# ESP32-S2 register map
Vendor: ESPRESSIF SYSTEMS (SHANGHAI) CO., LTD.; Series: ESP32 S-Series; File version: 20
CPU: Xtensa LX7 r0p0, little endian, no MPU, no FPU, 0 interrupt priority bits
Address unit: 32 bits
Registers are 32-bit, read-write, reset 0x0 unless marked. A register's access mark holds for its fields unless they carry their own. Offsets are from the block's base; [hi:lo] are bit positions; {n}, {i} and the like mark numbered series.

## INTERRUPT_CORE0 — Interrupt Controller (Core 0)
Base 0x3F4C2000
0x00 INTERRUPT_PRO_MAC_INTR_MAP reset 0x10 — MAC_INTR interrupt configuration register
  [4:0] INTERRUPT_PRO_MAC_INTR_MAP — This register is used to map MAC_INTR interrupt signal to one of the CPU interrupts.
0x04 INTERRUPT_PRO_MAC_NMI_MAP reset 0x10 — MAC_NMI interrupt configuration register
  [4:0] INTERRUPT_PRO_MAC_NMI_MAP — This register is used to map MAC_NMI interrupt signal to one of the CPU interrupts.
0x08 INTERRUPT_PRO_PWR_INTR_MAP reset 0x10 — PWR_INTR interrupt configuration register
  [4:0] INTERRUPT_PRO_PWR_INTR_MAP — This register is used to map PWR_INTR interrupt signal to one of the CPU interrupts.
0x0C INTERRUPT_PRO_BB_INT_MAP reset 0x10 — BB_INT interrupt configuration register
  [4:0] INTERRUPT_PRO_BB_INT_MAP — This register is used to map BB_INT interrupt signal to one of the CPU interrupts.
0x10 INTERRUPT_PRO_BT_MAC_INT_MAP reset 0x10 — BT_MAC_INT interrupt configuration register
  [4:0] INTERRUPT_PRO_BT_MAC_INT_MAP — This register is used to map BT_MAC_INT interrupt signal to one of the CPU interrupts.
0x14 INTERRUPT_PRO_BT_BB_INT_MAP reset 0x10 — BT_BB_INT interrupt configuration register
  [4:0] INTERRUPT_PRO_BT_BB_INT_MAP — This register is used to map BT_BB_INT interrupt signal to one of the CPU interrupts.
0x18 INTERRUPT_PRO_BT_BB_NMI_MAP reset 0x10 — BT_BB_NMI interrupt configuration register
  [4:0] INTERRUPT_PRO_BT_BB_NMI_MAP — This register is used to map BT_BB_NMI interrupt signal to one of the CPU interrupts.
0x1C INTERRUPT_PRO_RWBT_IRQ_MAP reset 0x10 — RWBT_IRQ interrupt configuration register
  [4:0] INTERRUPT_PRO_RWBT_IRQ_MAP — This register is used to map RWBT_IRQ interrupt signal to one of the CPU interrupts.
0x20 INTERRUPT_PRO_RWBLE_IRQ_MAP reset 0x10 — RWBLE_IRQ interrupt configuration register
  [4:0] INTERRUPT_PRO_RWBLE_IRQ_MAP — This register is used to map RWBLE_IRQ interrupt signal to one of the CPU interrupts.
0x24 INTERRUPT_PRO_RWBT_NMI_MAP reset 0x10 — RWBT_NMI interrupt configuration register
  [4:0] INTERRUPT_PRO_RWBT_NMI_MAP — This register is used to map RWBT_NMI interrupt signal to one of the CPU interrupts.
0x28 INTERRUPT_PRO_RWBLE_NMI_MAP reset 0x10 — RWBLE_NMI interrupt configuration register
  [4:0] INTERRUPT_PRO_RWBLE_NMI_MAP — This register is used to map RWBLE_NMI interrupt signal to one of the CPU interrupts.
0x2C INTERRUPT_PRO_SLC0_INTR_MAP reset 0x10 — SLC0_INTR interrupt configuration register
  [4:0] INTERRUPT_PRO_SLC0_INTR_MAP — This register is used to map SLC0_INTR interrupt signal to one of the CPU interrupts.
0x30 INTERRUPT_PRO_SLC1_INTR_MAP reset 0x10 — SLC1_INTR interrupt configuration register
  [4:0] INTERRUPT_PRO_SLC1_INTR_MAP — This register is used to map SLC1_INTR interrupt signal to one of the CPU interrupts.
0x34 INTERRUPT_PRO_UHCI0_INTR_MAP reset 0x10 — UHCI0_INTR interrupt configuration register
  [4:0] INTERRUPT_PRO_UHCI0_INTR_MAP — This register is used to map UHCI0_INTR interrupt signal to one of the CPU interrupts.
0x38 INTERRUPT_PRO_UHCI1_INTR_MAP reset 0x10 — UHCI1_INTR interrupt configuration register
  [4:0] INTERRUPT_PRO_UHCI1_INTR_MAP — This register is used to map UHCI1_INTR interrupt signal to one of the CPU interrupts.
0x3C INTERRUPT_PRO_TG_T0_LEVEL_INT_MAP reset 0x10 — TG_T0_LEVEL_INT interrupt configuration register
  [4:0] INTERRUPT_PRO_TG_T0_LEVEL_INT_MAP — This register is used to map TG_T0_LEVEL_INT interrupt signal to one of the CPU interrupts.
0x40 INTERRUPT_PRO_TG_T1_LEVEL_INT_MAP reset 0x10 — TG_T1_LEVEL_INT interrupt configuration register
  [4:0] INTERRUPT_PRO_TG_T1_LEVEL_INT_MAP — This register is used to map TG_T1_LEVEL_INT interrupt signal to one of the CPU interrupts.
0x44 INTERRUPT_PRO_TG_WDT_LEVEL_INT_MAP reset 0x10 — TG_WDT_LEVEL_INT interrupt configuration register
  [4:0] INTERRUPT_PRO_TG_WDT_LEVEL_INT_MAP — This register is used to map TG_WDT_LEVEL_INT interrupt signal to one of the CPU interrupts.
0x48 INTERRUPT_PRO_TG_LACT_LEVEL_INT_MAP reset 0x10 — TG_LACT_LEVEL_INT interrupt configuration register
  [4:0] INTERRUPT_PRO_TG_LACT_LEVEL_INT_MAP — This register is used to map TG_LACT_LEVEL_INT interrupt signal to one of the CPU interrupts.
0x4C INTERRUPT_PRO_TG1_T0_LEVEL_INT_MAP reset 0x10 — TG1_T0_LEVEL_INT interrupt configuration register
  [4:0] INTERRUPT_PRO_TG1_T0_LEVEL_INT_MAP — This register is used to map TG1_T0_LEVEL_INT interrupt signal to one of the CPU interrupts.
0x50 INTERRUPT_PRO_TG1_T1_LEVEL_INT_MAP reset 0x10 — TG1_T1_LEVEL_INT interrupt configuration register
  [4:0] INTERRUPT_PRO_TG1_T1_LEVEL_INT_MAP — This register is used to map TG1_T1_LEVEL_INT interrupt signal to one of the CPU interrupts.
0x54 INTERRUPT_PRO_TG1_WDT_LEVEL_INT_MAP reset 0x10 — TG1_WDT_LEVEL_INT interrupt configuration register
  [4:0] INTERRUPT_PRO_TG1_WDT_LEVEL_INT_MAP — This register is used to map TG1_WDT_LEVEL_INT interrupt signal to one of the CPU interrupts.
0x58 INTERRUPT_PRO_TG1_LACT_LEVEL_INT_MAP reset 0x10 — TG1_LACT_LEVEL_INT interrupt configuration register
  [4:0] INTERRUPT_PRO_TG1_LACT_LEVEL_INT_MAP — This register is used to map TG1_LACT_LEVEL_INT interrupt signal to one of the CPU interrupts.
0x5C INTERRUPT_PRO_GPIO_INTERRUPT_PRO_MAP reset 0x10 — GPIO_INTERRUPT_PRO interrupt configuration register
  [4:0] INTERRUPT_PRO_GPIO_INTERRUPT_PRO_MAP — This register is used to map GPIO_INTERRUPT_PRO interrupt signal to one of the CPU interrupts.
0x60 INTERRUPT_PRO_GPIO_INTERRUPT_PRO_NMI_MAP reset 0x10 — GPIO_INTERRUPT_PRO_NMI interrupt configuration register
  [4:0] INTERRUPT_PRO_GPIO_INTERRUPT_PRO_NMI_MAP — This register is used to map GPIO_INTERRUPT_PRO_NMI interrupt signal to one of the CPU interrupts.
0x64 INTERRUPT_PRO_GPIO_INTERRUPT_APP_MAP reset 0x10 — GPIO_INTERRUPT_APP interrupt configuration register
  [4:0] INTERRUPT_PRO_GPIO_INTERRUPT_APP_MAP — This register is used to map GPIO_INTERRUPT_APP interrupt signal to one of the CPU interrupts.
0x68 INTERRUPT_PRO_GPIO_INTERRUPT_APP_NMI_MAP reset 0x10 — GPIO_INTERRUPT_APP_NMI interrupt configuration register
  [4:0] INTERRUPT_PRO_GPIO_INTERRUPT_APP_NMI_MAP — This register is used to map GPIO_INTERRUPT_APP_NMI interrupt signal to one of the CPU interrupts.
0x6C INTERRUPT_PRO_DEDICATED_GPIO_IN_INTR_MAP reset 0x10 — DEDICATED_GPIO_IN_INTR interrupt configuration register
  [4:0] INTERRUPT_PRO_DEDICATED_GPIO_IN_INTR_MAP — This register is used to map DEDICATED_GPIO_IN_INTR interrupt signal to one of the CPU interrupts.
{0x70+4i} INTERRUPT_PRO_CPU_INTR_FROM_CPU_{i}_MAP reset 0x10 (i=0..3) — CPU_INTR_FROM_CPU_{i} interrupt configuration register
  [4:0] INTERRUPT_PRO_CPU_INTR_FROM_CPU_{i}_MAP — This register is used to map CPU_INTR_FROM_CPU_{i} interrupt signal to one of the CPU interrupts.
{0x7C+4i} INTERRUPT_PRO_SPI_INTR_{i}_MAP reset 0x10 (i=1..3) — SPI_INTR_{i} interrupt configuration register
  [4:0] INTERRUPT_PRO_SPI_INTR_{i}_MAP — This register is used to map SPI_INTR_{i} interrupt signal to one of the CPU interrupts.
0x8C INTERRUPT_PRO_I2S0_INT_MAP reset 0x10 — I2S0_INT interrupt configuration register
  [4:0] INTERRUPT_PRO_I2S0_INT_MAP — This register is used to map I2S0_INT interrupt signal to one of the CPU interrupts.
0x90 INTERRUPT_PRO_I2S1_INT_MAP reset 0x10 — I2S1_INT interrupt configuration register
  [4:0] INTERRUPT_PRO_I2S1_INT_MAP — This register is used to map I2S1_INT interrupt signal to one of the CPU interrupts.
0x94 INTERRUPT_PRO_UART_INTR_MAP reset 0x10 — UART_INT interrupt configuration register
  [4:0] INTERRUPT_PRO_UART_INTR_MAP — This register is used to map UART_INT interrupt signal to one of the CPU interrupts.
0x98 INTERRUPT_PRO_UART1_INTR_MAP reset 0x10 — UART1_INT interrupt configuration register
  [4:0] INTERRUPT_PRO_UART1_INTR_MAP — This register is used to map UART1_INT interrupt signal to one of the CPU interrupts.
0x9C INTERRUPT_PRO_UART2_INTR_MAP reset 0x10 — UART2_INT interrupt configuration register
  [4:0] INTERRUPT_PRO_UART2_INTR_MAP — This register is used to map UART2_INT interrupt signal to one of the CPU interrupts.
0xA0 INTERRUPT_PRO_SDIO_HOST_INTERRUPT_MAP reset 0x10 — SDIO_HOST_INTERRUPT configuration register
  [4:0] INTERRUPT_PRO_SDIO_HOST_INTERRUPT_MAP — This register is used to map SDIO_HOST_INTERRUPT signal to one of the CPU interrupts.
{0xA4+4i} INTERRUPT_PRO_PWM{i}_INTR_MAP reset 0x10 (i=0..3) — PWM{i}_INTR interrupt configuration register
  [4:0] INTERRUPT_PRO_PWM{i}_INTR_MAP — This register is used to map PWM{i}_INTR interrupt signal to one of the CPU interrupts.
0xB4 INTERRUPT_PRO_LEDC_INT_MAP reset 0x10 — LEDC_INTR interrupt configuration register
  [4:0] INTERRUPT_PRO_LEDC_INT_MAP — This register is used to map LEDC_INTR interrupt signal to one of the CPU interrupts.
0xB8 INTERRUPT_PRO_EFUSE_INT_MAP reset 0x10 — EFUSE_INT interrupt configuration register
  [4:0] INTERRUPT_PRO_EFUSE_INT_MAP — This register is used to map EFUSE_INT interrupt signal to one of the CPU interrupts.
0xBC INTERRUPT_PRO_CAN_INT_MAP reset 0x10 — CAN_INT interrupt configuration register
  [4:0] INTERRUPT_PRO_CAN_INT_MAP — This register is used to map CAN_INT interrupt signal to one of the CPU interrupts.
0xC0 INTERRUPT_PRO_USB_INTR_MAP reset 0x10 — USB_INT interrupt configuration register
  [4:0] INTERRUPT_PRO_USB_INTR_MAP — This register is used to map USB_INT interrupt signal to one of the CPU interrupts.
0xC4 INTERRUPT_PRO_RTC_CORE_INTR_MAP reset 0x10 — RTC_CORE_INTR interrupt configuration register
  [4:0] INTERRUPT_PRO_RTC_CORE_INTR_MAP — This register is used to map RTC_CORE_INTR interrupt signal to one of the CPU interrupts.
0xC8 INTERRUPT_PRO_RMT_INTR_MAP reset 0x10 — RMT_INTR interrupt configuration register
  [4:0] INTERRUPT_PRO_RMT_INTR_MAP — This register is used to map RMT_INTR interrupt signal to one of the CPU interrupts.
0xCC INTERRUPT_PRO_PCNT_INTR_MAP reset 0x10 — PCNT_INTR interrupt configuration register
  [4:0] INTERRUPT_PRO_PCNT_INTR_MAP — This register is used to map PCNT_INTR interrupt signal to one of the CPU interrupts.
0xD0 INTERRUPT_PRO_I2C_EXT0_INTR_MAP reset 0x10 — I2C_EXT0_INTR interrupt configuration register
  [4:0] INTERRUPT_PRO_I2C_EXT0_INTR_MAP — This register is used to map I2C_EXT0_INTR interrupt signal to one of the CPU interrupts.
0xD4 INTERRUPT_PRO_I2C_EXT1_INTR_MAP reset 0x10 — I2C_EXT1_INTR interrupt configuration register
  [4:0] INTERRUPT_PRO_I2C_EXT1_INTR_MAP — This register is used to map I2C_EXT1_INTR interrupt signal to one of the CPU interrupts.
0xD8 INTERRUPT_PRO_RSA_INTR_MAP reset 0x10 — RSA_INTR interrupt configuration register
  [4:0] INTERRUPT_PRO_RSA_INTR_MAP — This register is used to map RSA_INTR interrupt signal to one of the CPU interrupts.
0xDC INTERRUPT_PRO_SHA_INTR_MAP reset 0x10 — SHA_INTR interrupt configuration register
  [4:0] INTERRUPT_PRO_SHA_INTR_MAP — This register is used to map SHA_INTR interrupt signal to one of the CPU interrupts.
0xE0 INTERRUPT_PRO_AES_INTR_MAP reset 0x10 — AES_INTR interrupt configuration register
  [4:0] INTERRUPT_PRO_AES_INTR_MAP — This register is used to map AES_INTR interrupt signal to one of the CPU interrupts.
0xE4 INTERRUPT_PRO_SPI2_DMA_INT_MAP reset 0x10 — SPI2_DMA_INT interrupt configuration register
  [4:0] INTERRUPT_PRO_SPI2_DMA_INT_MAP — This register is used to map AES_INTR interrupt signal to one of the CPU interrupts.
0xE8 INTERRUPT_PRO_SPI3_DMA_INT_MAP reset 0x10 — SPI3_DMA_INT interrupt configuration register
  [4:0] INTERRUPT_PRO_SPI3_DMA_INT_MAP — This register is used to map SPI3_DMA_INT dma interrupt signal to one of the CPU interrupts.
0xEC INTERRUPT_PRO_WDG_INT_MAP reset 0x10 — WDG_INT interrupt configuration register
  [4:0] INTERRUPT_PRO_WDG_INT_MAP — This register is used to map WDG_INT interrupt signal to one of the CPU interrupts.
0xF0 INTERRUPT_PRO_TIMER_INT1_MAP reset 0x10 — TIMER_INT1 interrupt configuration register
  [4:0] INTERRUPT_PRO_TIMER_INT1_MAP — This register is used to map TIMER_INT1 interrupt signal to one of the CPU interrupts.
0xF4 INTERRUPT_PRO_TIMER_INT2_MAP reset 0x10 — TIMER_INT2 interrupt configuration register
  [4:0] INTERRUPT_PRO_TIMER_INT2_MAP — This register is used to map TIMER_INT2 interrupt signal to one of the CPU interrupts.
0xF8 INTERRUPT_PRO_TG_T0_EDGE_INT_MAP reset 0x10 — TG_T0_EDGE_INT interrupt configuration register
  [4:0] INTERRUPT_PRO_TG_T0_EDGE_INT_MAP — This register is used to map TG_T0_EDGE_INT interrupt signal to one of the CPU interrupts.
0xFC INTERRUPT_PRO_TG_T1_EDGE_INT_MAP reset 0x10 — TG_T1_EDGE_INT interrupt configuration register
  [4:0] INTERRUPT_PRO_TG_T1_EDGE_INT_MAP — This register is used to map TG_T1_EDGE_INT interrupt signal to one of the CPU interrupts.
0x100 INTERRUPT_PRO_TG_WDT_EDGE_INT_MAP reset 0x10 — TG_WDT_EDGE_INT interrupt configuration register
  [4:0] INTERRUPT_PRO_TG_WDT_EDGE_INT_MAP — This register is used to map TG_WDT_EDGE_INT interrupt signal to one of the CPU interrupts.
0x104 INTERRUPT_PRO_TG_LACT_EDGE_INT_MAP reset 0x10 — TG_LACT_EDGE_INT interrupt configuration register
  [4:0] INTERRUPT_PRO_TG_LACT_EDGE_INT_MAP — This register is used to map TG_LACT_EDGE_INT interrupt signal to one of the CPU interrupts.
0x108 INTERRUPT_PRO_TG1_T0_EDGE_INT_MAP reset 0x10 — TG1_T0_EDGE_INT interrupt configuration register
  [4:0] INTERRUPT_PRO_TG1_T0_EDGE_INT_MAP — This register is used to map TG1_T0_EDGE_INT interrupt signal to one of the CPU interrupts.
0x10C INTERRUPT_PRO_TG1_T1_EDGE_INT_MAP reset 0x10 — TG1_T1_EDGE_INT interrupt configuration register
  [4:0] INTERRUPT_PRO_TG1_T1_EDGE_INT_MAP — This register is used to map TG1_T1_EDGE_INT interrupt signal to one of the CPU interrupts.
0x110 INTERRUPT_PRO_TG1_WDT_EDGE_INT_MAP reset 0x10 — TG1_WDT_EDGE_INT interrupt configuration register
  [4:0] INTERRUPT_PRO_TG1_WDT_EDGE_INT_MAP — This register is used to map TG1_WDT_EDGE_INT interrupt signal to one of the CPU interrupts.
0x114 INTERRUPT_PRO_TG1_LACT_EDGE_INT_MAP reset 0x10 — TG1_LACT_EDGE_INT interrupt configuration register
  [4:0] INTERRUPT_PRO_TG1_LACT_EDGE_INT_MAP — This register is used to map TG1_LACT_EDGE_INT interrupt signal to one of the CPU interrupts.
0x118 INTERRUPT_PRO_CACHE_IA_INT_MAP reset 0x10 — CACHE_IA_INT interrupt configuration register
  [4:0] INTERRUPT_PRO_CACHE_IA_INT_MAP — This register is used to map CACHE_IA_INT interrupt signal to one of the CPU interrupts.
{0x11C+4i} INTERRUPT_PRO_SYSTIMER_TARGET{i}_INT_MAP reset 0x10 (i=0..2) — SYSTIMER_TARGET{i}_INT interrupt configuration register
  [4:0] INTERRUPT_PRO_SYSTIMER_TARGET{i}_INT_MAP — This register is used to map SYSTIMER_TARGET{i}_INT interrupt signal to one of the CPU interrupts.
0x128 INTERRUPT_PRO_ASSIST_DEBUG_INTR_MAP reset 0x10 — ASSIST_DEBUG_INTR interrupt configuration register
  [4:0] INTERRUPT_PRO_ASSIST_DEBUG_INTR_MAP — This register is used to map ASSIST_DEBUG_INTR interrupt signal to one of the CPU interrupts.
0x12C INTERRUPT_PRO_PMS_PRO_IRAM0_ILG_INTR_MAP reset 0x10 — PMS_PRO_IRAM0_ILG interrupt configuration register
  [4:0] INTERRUPT_PRO_PMS_PRO_IRAM0_ILG_INTR_MAP — This register is used to map PMS_PRO_IRAM0_ILG interrupt signal to one of the CPU interrupts.
0x130 INTERRUPT_PRO_PMS_PRO_DRAM0_ILG_INTR_MAP reset 0x10 — PMS_PRO_DRAM0_ILG interrupt configuration register
  [4:0] INTERRUPT_PRO_PMS_PRO_DRAM0_ILG_INTR_MAP — This register is used to map PMS_PRO_DRAM0_ILG interrupt signal to one of the CPU interrupts.
0x134 INTERRUPT_PRO_PMS_PRO_DPORT_ILG_INTR_MAP reset 0x10 — PMS_PRO_DPORT_ILG interrupt configuration register
  [4:0] INTERRUPT_PRO_PMS_PRO_DPORT_ILG_INTR_MAP — This register is used to map PMS_PRO_DPORT_ILG interrupt signal to one of the CPU interrupts.
0x138 INTERRUPT_PRO_PMS_PRO_AHB_ILG_INTR_MAP reset 0x10 — PMS_PRO_AHB_ILG interrupt configuration register
  [4:0] INTERRUPT_PRO_PMS_PRO_AHB_ILG_INTR_MAP — This register is used to map PMS_PRO_AHB_ILG interrupt signal to one of the CPU interrupts.
0x13C INTERRUPT_PRO_PMS_PRO_CACHE_ILG_INTR_MAP reset 0x10 — PMS_PRO_CACHE_ILG interrupt configuration register
  [4:0] INTERRUPT_PRO_PMS_PRO_CACHE_ILG_INTR_MAP — This register is used to map PMS_PRO_CACHE_ILG interrupt signal to one of the CPU interrupts.
0x140 INTERRUPT_PRO_PMS_DMA_APB_I_ILG_INTR_MAP reset 0x10 — PMS_DMA_APB_I_ILG interrupt configuration register
  [4:0] INTERRUPT_PRO_PMS_DMA_APB_I_ILG_INTR_MAP — This register is used to map PMS_DMA_APB_I_ILG interrupt signal to one of the CPU interrupts.
0x144 INTERRUPT_PRO_PMS_DMA_RX_I_ILG_INTR_MAP reset 0x10 — PMS_DMA_RX_I_ILG interrupt configuration register
  [4:0] INTERRUPT_PRO_PMS_DMA_RX_I_ILG_INTR_MAP — This register is used to map PMS_DMA_RX_I_ILG interrupt signal to one of the CPU interrupts.
0x148 INTERRUPT_PRO_PMS_DMA_TX_I_ILG_INTR_MAP reset 0x10 — PMS_DMA_TX_I_ILG interrupt configuration register
  [4:0] INTERRUPT_PRO_PMS_DMA_TX_I_ILG_INTR_MAP — This register is used to map PMS_DMA_TX_I_ILG interrupt signal to one of the CPU interrupts.
0x14C INTERRUPT_PRO_SPI_MEM_REJECT_INTR_MAP reset 0x10 — SPI_MEM_REJECT_INTR interrupt configuration register
  [4:0] INTERRUPT_PRO_SPI_MEM_REJECT_INTR_MAP — This register is used to map SPI_MEM_REJECT_INTR interrupt signal to one of the CPU interrupts.
0x150 INTERRUPT_PRO_DMA_COPY_INTR_MAP reset 0x10 — DMA_COPY_INTR interrupt configuration register
  [4:0] INTERRUPT_PRO_DMA_COPY_INTR_MAP — This register is used to map DMA_COPY_INTR interrupt signal to one of the CPU interrupts.
0x154 INTERRUPT_PRO_SPI4_DMA_INT_MAP reset 0x10 — SPI4_DMA_INT interrupt configuration register
  [4:0] INTERRUPT_PRO_SPI4_DMA_INT_MAP — This register is used to map SPI4_DMA_INT interrupt signal to one of the CPU interrupts.
0x158 INTERRUPT_PRO_SPI_INTR_4_MAP reset 0x10 — SPI_INTR_4 interrupt configuration register
  [4:0] INTERRUPT_PRO_SPI_INTR_4_MAP — This register is used to map SPI_INTR_4 interrupt signal to one of the CPU interrupts.
0x15C INTERRUPT_PRO_DCACHE_PRELOAD_INT_MAP reset 0x10 — DCACHE_PRELOAD_INT interrupt configuration register
  [4:0] INTERRUPT_PRO_DCACHE_PRELOAD_INT_MAP — This register is used to map DCACHE_PRELOAD_INT interrupt signal to one of the CPU interrupts.
0x160 INTERRUPT_PRO_ICACHE_PRELOAD_INT_MAP reset 0x10 — ICACHE_PRELOAD_INT interrupt configuration register
  [4:0] INTERRUPT_PRO_ICACHE_PRELOAD_INT_MAP — This register is used to map ICACHE_PRELOAD_INT interrupt signal to one of the CPU interrupts.
0x164 INTERRUPT_PRO_APB_ADC_INT_MAP reset 0x10 — APB_ADC_INT interrupt configuration register
  [4:0] INTERRUPT_PRO_APB_ADC_INT_MAP — This register is used to map APB_ADC_INT interrupt signal to one of the CPU interrupts.
0x168 INTERRUPT_PRO_CRYPTO_DMA_INT_MAP reset 0x10 — CRYPTO_DMA_INT interrupt configuration register
  [4:0] INTERRUPT_PRO_CRYPTO_DMA_INT_MAP — This register is used to map CRYPTO_DMA_INT interrupt signal to one of the CPU interrupts.
0x16C INTERRUPT_PRO_CPU_PERI_ERROR_INT_MAP reset 0x10 — CPU_PERI_ERROR_INT interrupt configuration register
  [4:0] INTERRUPT_PRO_CPU_PERI_ERROR_INT_MAP — This register is used to map CPU_PERI_ERROR_INT interrupt signal to one of the CPU interrupts.
0x170 INTERRUPT_PRO_APB_PERI_ERROR_INT_MAP reset 0x10 — APB_PERI_ERROR_INT interrupt configuration register
  [4:0] INTERRUPT_PRO_APB_PERI_ERROR_INT_MAP — This register is used to map APB_PERI_ERROR_INT interrupt signal to one of the CPU interrupts.
0x174 INTERRUPT_PRO_DCACHE_SYNC_INT_MAP reset 0x10 — DCACHE_SYNC_INT interrupt configuration register
  [4:0] INTERRUPT_PRO_DCACHE_SYNC_INT_MAP — This register is used to map DCACHE_SYNC_INT interrupt signal to one of the CPU interrupts.
0x178 INTERRUPT_PRO_ICACHE_SYNC_INT_MAP reset 0x10 — ICACHE_SYNC_INT interrupt configuration register
  [4:0] INTERRUPT_PRO_ICACHE_SYNC_INT_MAP — This register is used to map ICACHE_SYNC_INT interrupt signal to one of the CPU interrupts.
0x17C INTERRUPT_PRO_INTR_STATUS_REG_0 ro — Interrupt status register 0
  [31:0] INTERRUPT_PRO_INTR_STATUS_0 — This register stores the status of the first 32 input interrupt sources.
0x180 INTERRUPT_PRO_INTR_STATUS_REG_1 ro — Interrupt status register 1
  [31:0] INTERRUPT_PRO_INTR_STATUS_1 — This register stores the status of the second 32 input interrupt sources.
0x184 INTERRUPT_PRO_INTR_STATUS_REG_2 ro — Interrupt status register 2
  [31:0] INTERRUPT_PRO_INTR_STATUS_2 — This register stores the status of the last 31 input interrupt sources.
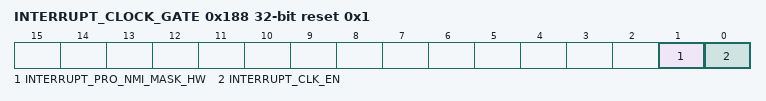
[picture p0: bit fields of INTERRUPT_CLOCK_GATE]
0x188 INTERRUPT_CLOCK_GATE reset 0x1 — NMI interrupt signals mask register
  [1] INTERRUPT_PRO_NMI_MASK_HW — This bit is used to disable all NMI interrupt signals to CPU.
  [0] INTERRUPT_CLK_EN — This bit is used to enable or disable the clock of interrupt matrix. 1: enable the clock. 0: disable the clock.
0xFFC INTERRUPT_REG_DATE reset 0x1904180 — Version control register
  [27:0] INTERRUPT_INTERRUPT_REG_DATE — This is the version register.
